# STM32H7B3 register map
File version: 3.3
CPU: CM7 r0p1, little endian, MPU, FPU, 4 interrupt priority bits
Registers are 32-bit, read-write, reset 0x0 unless marked. A register's access mark holds for its fields unless they carry their own. Offsets are from the block's base; [hi:lo] are bit positions; {n}, {i} and the like mark numbered series.

## SYSCFG — System configuration controller
Base 0x58000400
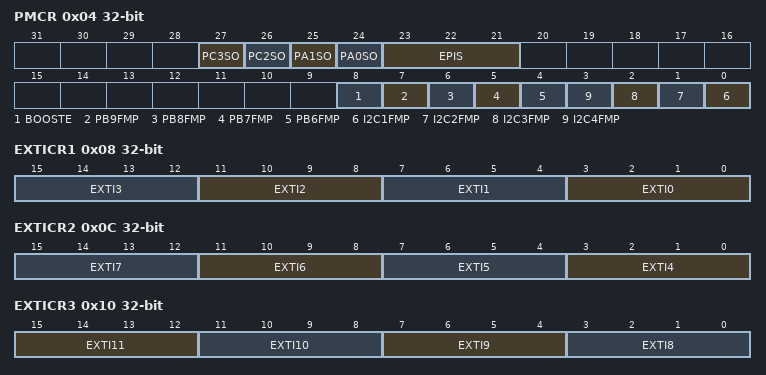
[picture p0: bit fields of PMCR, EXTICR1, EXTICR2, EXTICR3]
0x04 PMCR — peripheral mode configuration register
  [27] PC3SO — PC3 Switch Open
  [26] PC2SO — PC2 Switch Open
  [25] PA1SO — PA1 Switch Open
  [24] PA0SO — PA0 Switch Open
  [23:21] EPIS — Ethernet PHY Interface Selection
  [8] BOOSTE — Booster Enable
  [7] PB9FMP — PB(9) Fm+
  [6] PB8FMP — PB(8) Fast Mode Plus
  [5] PB7FMP — PB(7) Fast Mode Plus
  [4] PB6FMP — PB(6) Fm+
  [n-1] I2C{n}FMP (n=1..4) — I2C{n} Fm+
0x08 EXTICR1 — external interrupt configuration register 1
  [4n+3:4n] EXTI{n} (n=0..3) — EXTI x configuration (x = 0 to 3)
0x0C EXTICR2 — external interrupt configuration register 2
  [4n-13:4n-16] EXTI{n} (n=4..7) — EXTI x configuration (x = 4 to 7)
0x10 EXTICR3 — external interrupt configuration register 3
  [15:12] EXTI11 — EXTI x configuration (x = 8 to 11)
  [11:8] EXTI10
  [7:4] EXTI9 — EXTI x configuration (x = 8 to 11)
  [3:0] EXTI8 — EXTI x configuration (x = 8 to 11)
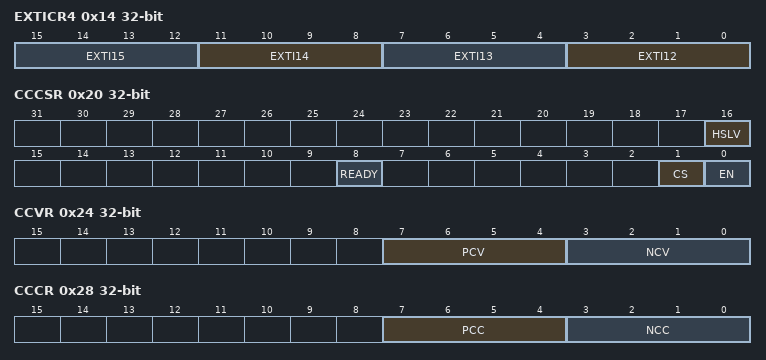
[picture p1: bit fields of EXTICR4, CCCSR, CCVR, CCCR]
0x14 EXTICR4 — external interrupt configuration register 4
  [4n-45:4n-48] EXTI{n} (n=12..15) — EXTI x configuration (x = 12 to 15)
0x20 CCCSR — compensation cell control/status register
  [16] HSLV — High-speed at low-voltage
  [8] READY — Compensation cell ready flag
  [1] CS — Code selection
  [0] EN — enable
0x24 CCVR ro — SYSCFG compensation cell value register
  [7:4] PCV — PMOS compensation value
  [3:0] NCV — NMOS compensation value
0x28 CCCR — SYSCFG compensation cell code register
  [7:4] PCC — PMOS compensation code
  [3:0] NCC — NMOS compensation code
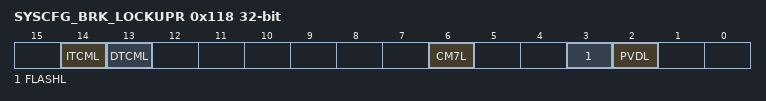
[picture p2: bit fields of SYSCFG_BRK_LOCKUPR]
0x118 SYSCFG_BRK_LOCKUPR — SYSCFG timer break lockup register
  [14] ITCML — ITCM double ECC error signal lock
  [13] DTCML — D1TCM or D0TCM double ECC error signal lock
  [6] CM7L — Cortex-M7 LOCKUP (HardFault) output enable bit
  [3] FLASHL — Flash double ECC error lock bit
  [2] PVDL — PVD lock enable bit.

## TIM6 — Basic timers
Base 0x40001000
Same registers: TIM7 0x40001400
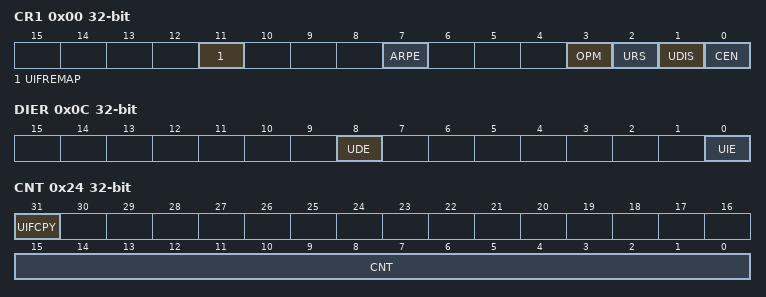
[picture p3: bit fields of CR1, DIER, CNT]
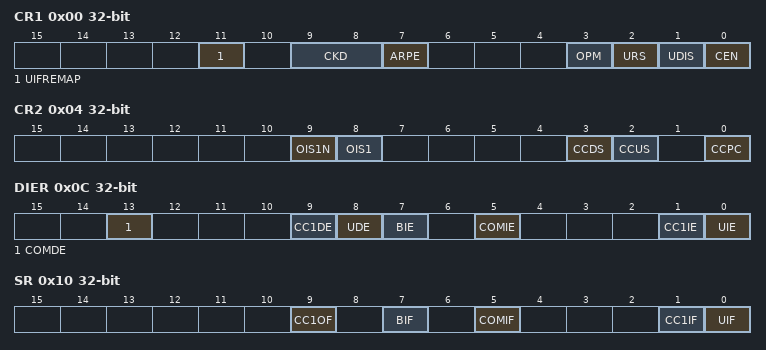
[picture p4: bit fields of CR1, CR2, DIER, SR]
0x00 CR1 — control register 1
  [11] UIFREMAP — UIF status bit remapping
  [7] ARPE — Auto-reload preload enable
  [3] OPM — One-pulse mode
  [2] URS — Update request source
  [1] UDIS — Update disable
  [0] CEN — Counter enable
0x04 CR2 — control register 2
  [6:4] MMS — Master mode selection
0x0C DIER — DMA/Interrupt enable register
  [8] UDE — Update DMA request enable
  [0] UIE — Update interrupt enable
0x10 SR — status register
  [0] UIF — Update interrupt flag
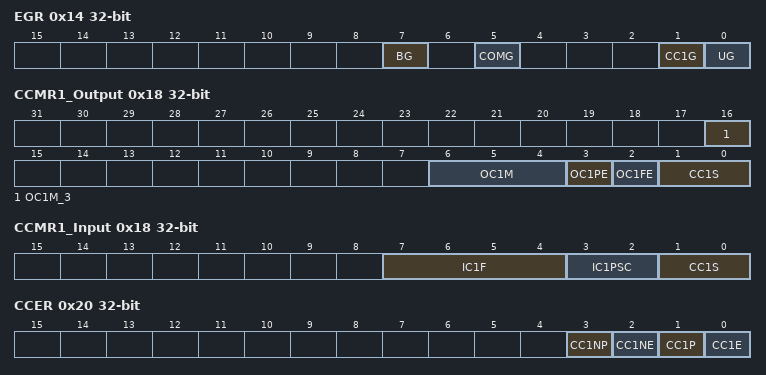
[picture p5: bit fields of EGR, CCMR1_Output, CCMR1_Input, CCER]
0x14 EGR wo — event generation register
  [0] UG — Update generation
0x24 CNT — counter
  [31] UIFCPY — UIF Copy
  [15:0] CNT — Low counter value
0x28 PSC — prescaler
  [15:0] PSC — Prescaler value
0x2C ARR — auto-reload register
  [15:0] ARR — Low Auto-reload value

## TIM16 — General-purpose-timers
Base 0x40014400
0x00 CR1 — control register 1
  [11] UIFREMAP — UIF status bit remapping
  [9:8] CKD — Clock division
  [7] ARPE — Auto-reload preload enable
  [3] OPM — One-pulse mode
  [2] URS — Update request source
  [1] UDIS — Update disable
  [0] CEN — Counter enable
0x04 CR2 — control register 2
  [9] OIS1N — Output Idle state 1
  [8] OIS1 — Output Idle state 1
  [3] CCDS — Capture/compare DMA selection
  [2] CCUS — Capture/compare control update selection
  [0] CCPC — Capture/compare preloaded control
0x0C DIER — DMA/Interrupt enable register
  [13] COMDE — COM DMA request enable
  [9] CC1DE — Capture/Compare 1 DMA request enable
  [8] UDE — Update DMA request enable
  [7] BIE — Break interrupt enable
  [5] COMIE — COM interrupt enable
  [1] CC1IE — Capture/Compare 1 interrupt enable
  [0] UIE — Update interrupt enable
0x10 SR — status register
  [9] CC1OF — Capture/Compare 1 overcapture flag
  [7] BIF — Break interrupt flag
  [5] COMIF — COM interrupt flag
  [1] CC1IF — Capture/compare 1 interrupt flag
  [0] UIF — Update interrupt flag
0x14 EGR wo — event generation register
  [7] BG — Break generation
  [5] COMG — Capture/Compare control update generation
  [1] CC1G — Capture/compare 1 generation
  [0] UG — Update generation
0x18 CCMR1_Output — capture/compare mode register (output mode)
  [16] OC1M_3 — Output Compare 1 mode
  [6:4] OC1M — Output Compare 1 mode
  [3] OC1PE — Output Compare 1 preload enable
  [2] OC1FE — Output Compare 1 fast enable
  [1:0] CC1S — Capture/Compare 1 selection
0x18 CCMR1_Input (alternate view of CCMR1_Output) — capture/compare mode register 1 (input mode)
  [7:4] IC1F — Input capture 1 filter
  [3:2] IC1PSC — Input capture 1 prescaler
  [1:0] CC1S — Capture/Compare 1 selection
0x20 CCER — capture/compare enable register
  [3] CC1NP — Capture/Compare 1 output Polarity
  [2] CC1NE — Capture/Compare 1 complementary output enable
  [1] CC1P — Capture/Compare 1 output Polarity
  [0] CC1E — Capture/Compare 1 output enable
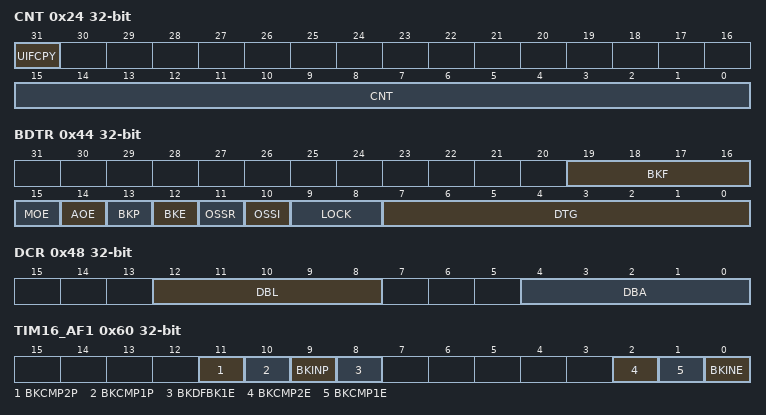
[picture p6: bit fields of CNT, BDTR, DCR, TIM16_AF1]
0x24 CNT access per field — counter
  [31] UIFCPY ro — UIF Copy
  [15:0] CNT rw — counter value
0x28 PSC — prescaler
  [15:0] PSC — Prescaler value
0x2C ARR — auto-reload register
  [15:0] ARR — Auto-reload value
0x30 RCR — repetition counter register
  [7:0] REP — Repetition counter value
0x34 CCR1 — capture/compare register 1
  [15:0] CCR1 — Capture/Compare 1 value
0x44 BDTR — break and dead-time register
  [19:16] BKF — Break filter
  [15] MOE — Main output enable
  [14] AOE — Automatic output enable
  [13] BKP — Break polarity
  [12] BKE — Break enable
  [11] OSSR — Off-state selection for Run mode
  [10] OSSI — Off-state selection for Idle mode
  [9:8] LOCK — Lock configuration
  [7:0] DTG — Dead-time generator setup
0x48 DCR — DMA control register
  [12:8] DBL — DMA burst length
  [4:0] DBA — DMA base address
0x4C DMAR — DMA address for full transfer
  [15:0] DMAB — DMA register for burst accesses
0x60 TIM16_AF1 — TIM16 alternate function register 1
  [11] BKCMP2P — BRK COMP2 input polarity
  [10] BKCMP1P — BRK COMP1 input polarity
  [9] BKINP — BRK BKIN input polarity
  [8] BKDFBK1E — BRK dfsdm1_break[1] enable
  [2] BKCMP2E — BRK COMP2 enable
  [1] BKCMP1E — BRK COMP1 enable
  [0] BKINE — BRK BKIN input enable
0x68 TIM16_TISEL — TIM16 input selection register
  [3:0] TI1SEL — selects TI1[0] to TI1[15] input

## TIM17 — General-purpose-timers
Base 0x40014800
Registers as TIM16 (with TIM16 read as TIM17).

## VREFBUF
Base 0x58003C00
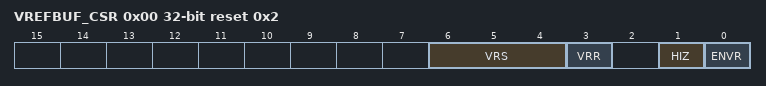
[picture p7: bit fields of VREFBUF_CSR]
0x00 VREFBUF_CSR access per field reset 0x2 — VREFBUF control and status register
  [6:4] VRS rw — Voltage reference scale These bits select the value generated by the voltage reference buffer. Other: Reserved
  [3] VRR ro — Voltage reference buffer ready
  [1] HIZ rw — High impedance mode This bit controls the analog switch to connect or not the VREF+ pin. Refer to Table196: VREF buffer modes for the mode descriptions depending on ENVR bit configuration.
  [0] ENVR rw — Voltage reference buffer mode enable This bit is used to enable the voltage reference buffer mode.
0x04 VREFBUF_CCR — VREFBUF calibration control register
  [5:0] TRIM — Trimming code These bits are automatically initialized after reset with the trimming value stored in the Flash memory during the production test. Writing into these bits allows to tune the internal reference buffer voltage.

## WWDG
Base 0x50003000
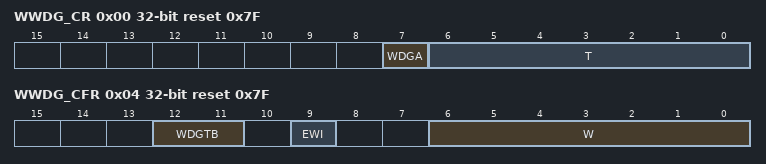
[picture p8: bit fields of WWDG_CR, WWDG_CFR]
0x00 WWDG_CR reset 0x7F — Control register
  [7] WDGA — Activation bit This bit is set by software and only cleared by hardware after a reset. When WDGA=1, the watchdog can generate a reset.
  [6:0] T — 7-bit counter (MSB to LSB) These bits contain the value of the watchdog counter. It is decremented every (4096 x 2WDGTB[1:0]) PCLK cycles. A reset is produced when it is decremented from 0x40 to 0x3F (T6 becomes cleared).
0x04 WWDG_CFR reset 0x7F — Configuration register
  [12:11] WDGTB — Timer base The time base of the prescaler can be modified as follows:
  [9] EWI — Early wakeup interrupt When set, an interrupt occurs whenever the counter reaches the value 0x40. This interrupt is only cleared by hardware after a reset.
  [6:0] W — 7-bit window value These bits contain the window value to be compared to the downcounter.
0x08 WWDG_SR — Status register
  [0] EWIF — Early wakeup interrupt flag This bit is set by hardware when the counter has reached the value 0x40. It must be cleared by software by writing 0. A write of 1 has no effect. This bit is also set if the interrupt is not enabled.
